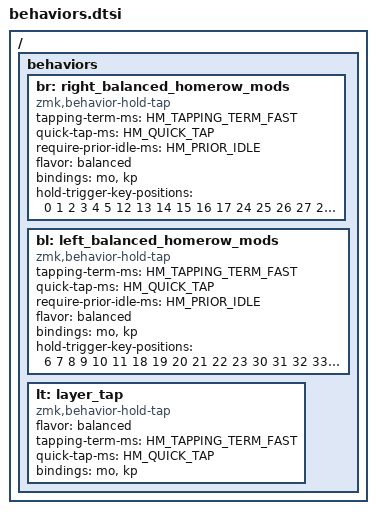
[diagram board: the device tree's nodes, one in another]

#define HM_TAPPING_TERM 300
#define HM_TAPPING_TERM_FAST 200
#define HM_PRIOR_IDLE 150
#define HM_QUICK_TAP 125



/ {
  
 behaviors {
    br: right_balanced_homerow_mods {
        compatible = "zmk,behavior-hold-tap";
        #binding-cells = <2>;
        tapping-term-ms = <HM_TAPPING_TERM_FAST>;    
        quick-tap-ms = <HM_QUICK_TAP>;
        require-prior-idle-ms = <HM_PRIOR_IDLE>;
        flavor = "balanced";
        bindings = <&mo>, <&kp>;
        hold-trigger-key-positions = <0 1 2 3 4 5 12 13 14 15 16 17 24 25 26 27 28 29 36 37 41 42 43 47 48 49>;
        };

    bl: left_balanced_homerow_mods {
        compatible = "zmk,behavior-hold-tap";
        #binding-cells = <2>;
        tapping-term-ms = <HM_TAPPING_TERM_FAST>;    
        quick-tap-ms = <HM_QUICK_TAP>;
        require-prior-idle-ms = <HM_PRIOR_IDLE>;
        flavor = "balanced";
        bindings = <&mo>, <&kp>;
        hold-trigger-key-positions = <6 7 8 9 10 11 18 19 20 21 22 23 30 31 32 33 34 35 38 39 40 44 45 46>;
        };

    lt: layer_tap {
        compatible = "zmk,behavior-hold-tap";
        flavor = "balanced";
        tapping-term-ms = <HM_TAPPING_TERM_FAST>;
        quick-tap-ms = <HM_QUICK_TAP>;
        bindings = <&mo> <&kp >;
        #binding-cells = < 2 >;
        };
    };  

};
   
